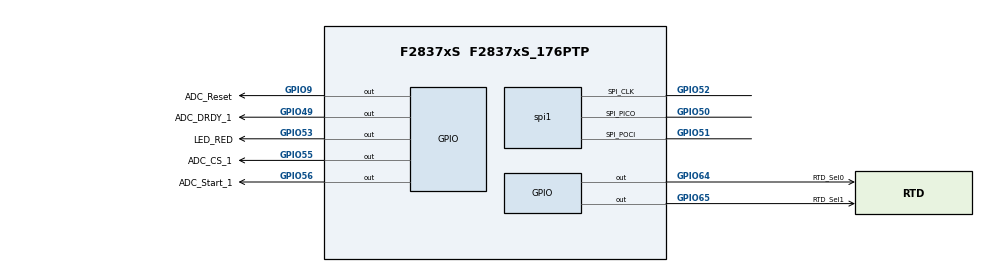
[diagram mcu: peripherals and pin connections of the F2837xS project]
/**
 * @cliArgs --device "F2837xS" --part "F2837xS_176PTP" --package "F2837xS_176PTP" --context "system" --product "C2000WARE@5.04.00.00"
 * @versions {"tool":"1.22.0+3893"}
 */

/**
 * Import the modules used in this configuration.
 */
const gpio  = scripting.addModule("/driverlib/gpio.js", {}, false);
const gpio1 = gpio.addInstance();
const gpio2 = gpio.addInstance();
const gpio3 = gpio.addInstance();
const gpio4 = gpio.addInstance();
const gpio5 = gpio.addInstance();
const gpio6 = gpio.addInstance();
const gpio7 = gpio.addInstance();
const spi   = scripting.addModule("/driverlib/spi.js", {}, false);
const spi1  = spi.addInstance();

/**
 * Write custom configuration values to the imported modules.
 */
gpio1.$name           = "ADC_CS_1";
gpio1.direction       = "GPIO_DIR_MODE_OUT";
gpio1.gpioPin.$assign = "GPIO55";

gpio2.$name           = "ADC_Start_1";
gpio2.direction       = "GPIO_DIR_MODE_OUT";
gpio2.gpioPin.$assign = "GPIO56";

gpio3.$name           = "ADC_Reset";
gpio3.gpioPin.$assign = "GPIO9";

gpio4.$name           = "RTD_Sel0";
gpio4.direction       = "GPIO_DIR_MODE_OUT";
gpio4.gpioPin.$assign = "GPIO64";

gpio5.$name           = "RTD_Sel1";
gpio5.direction       = "GPIO_DIR_MODE_OUT";
gpio5.gpioPin.$assign = "GPIO65";

gpio6.$name           = "ADC_DRDY_1";
gpio6.gpioPin.$assign = "GPIO49";

gpio7.$name           = "LED_RED";
gpio7.direction       = "GPIO_DIR_MODE_OUT";
gpio7.gpioPin.$assign = "GPIO53";

spi1.$name                   = "mySPI0";
spi1.useInterrupts           = false;
spi1.mode                    = "SPI_MODE_CONTROLLER";
spi1.useFifo                 = false;
spi1.bitRate                 = 2000000;
spi1.emulationMode           = "SPI_EMULATION_FREE_RUN";
spi1.dataWidth               = "8";
spi1.spi.$assign             = "SPIC";
spi1.spi.spi_picoPin.$assign = "GPIO50";
spi1.spi.spi_pociPin.$assign = "GPIO51";
spi1.spi.spi_clkPin.$assign  = "GPIO52";
spi1.picoQual.$name          = "myGPIOQUAL0";
spi1.picoQual.qualMode       = "GPIO_QUAL_SYNC";
spi1.pociQual.$name          = "myGPIOQUAL1";
spi1.pociQual.qualMode       = "GPIO_QUAL_SYNC";
spi1.clkQual.$name           = "myGPIOQUAL2";
spi1.clkQual.qualMode        = "GPIO_QUAL_SYNC";
spi1.pteQual.$name           = "myGPIOQUAL3";

/**
 * Pinmux solution for unlocked pins/peripherals. This ensures that minor changes to the automatic solver in a future
 * version of the tool will not impact the pinmux you originally saw.  These lines can be completely deleted in order to
 * re-solve from scratch.
 */
spi1.spi.spi_ptePin.$suggestSolution = "GPIO72";
